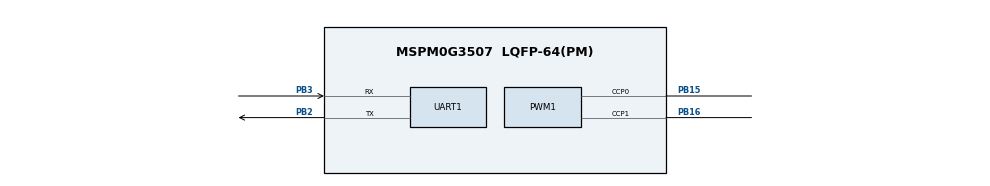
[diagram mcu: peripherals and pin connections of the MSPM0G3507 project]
//@cliArgs --device "MSPM0G350X" --package "LQFP-64(PM)" --part "Default"
//@v2CliArgs --device "MSPM0G3507" --package "LQFP-64(PM)"
// @cliArgs --board /ti/boards/LP_MSPM0G3507 --rtos nortos

/**
 * Import the modules used in this configuration.
 */
const SYSCTL = scripting.addModule("/ti/driverlib/SYSCTL");
const UART   = scripting.addModule("/ti/driverlib/UART", {}, false);
const UART1  = UART.addInstance();
const PWM    = scripting.addModule("/ti/driverlib/PWM", {}, false);
const PWM1   = PWM.addInstance();
const GPIO   = scripting.addModule("/ti/driverlib/GPIO", {}, false);
const GPIO1  = GPIO.addInstance();
const GPIO2  = GPIO.addInstance();
const GPIO3  = GPIO.addInstance();
const GPIO4  = GPIO.addInstance();
const GPIO5  = GPIO.addInstance();
const GPIO6  = GPIO.addInstance();
const GPIO7  = GPIO.addInstance();
const GPIO8  = GPIO.addInstance();
const GPIO9  = GPIO.addInstance();
const GPIO10 = GPIO.addInstance();
const GPIO11 = GPIO.addInstance();
const GPIO12 = GPIO.addInstance();
const GPIO13 = GPIO.addInstance();

/**
 * Write custom configuration values to the imported modules.
 */

const Board = scripting.addModule("/ti/driverlib/Board", {}, false);

SYSCTL.forceDefaultClkConfig = true;

UART1.$name = "UART_VISION";
UART1.profile = "CONFIG_PROFILE_1";
UART1.peripheral.$assign = "UART3";
UART1.targetBaudRate = 115200;
UART1.enableInternalLoopback = false;
UART1.enabledInterrupts = ["RX"];
UART1.enableFIFO = false;
UART1.peripheral.txPin.$assign = "PB2";
UART1.peripheral.rxPin.$assign = "PB3";

PWM1.$name                      = "PWM_MOTOR";
PWM1.pwmMode                    = "EDGE_ALIGN_UP";
PWM1.clockSource                = "BUSCLK";
PWM1.clockDivider               = 1;
PWM1.clockPrescale              = 1;
/* DriverLib writes LOAD = timerCount - 1: 32 MHz / 1600 = 20 kHz. */
PWM1.timerCount                 = 1600;
PWM1.timerStartTimer            = false;
PWM1.enableShadowLoad           = false;
PWM1.peripheral.$assign         = "TIMG8";
PWM1.peripheral.ccp0Pin.$assign = "PB15";
PWM1.peripheral.ccp1Pin.$assign = "PB16";
PWM1.PWM_CHANNEL_0.$name        = "MOTOR_A_PWM";
PWM1.PWM_CHANNEL_0.dutyCycle    = 0;
PWM1.PWM_CHANNEL_0.shadowUpdateMode = "IMMEDIATE";
PWM1.PWM_CHANNEL_1.$name        = "MOTOR_B_PWM";
PWM1.PWM_CHANNEL_1.dutyCycle    = 0;
PWM1.PWM_CHANNEL_1.shadowUpdateMode = "IMMEDIATE";

GPIO1.$name                             = "GPIO_TB6612_A";
GPIO1.port                              = "PORTA";
GPIO1.associatedPins.create(2);
GPIO1.associatedPins[0].$name           = "AIN2";
GPIO1.associatedPins[0].assignedPin     = "12";
GPIO1.associatedPins[0].initialValue    = "CLEARED";
GPIO1.associatedPins[1].$name           = "AIN1";
GPIO1.associatedPins[1].assignedPin     = "13";
GPIO1.associatedPins[1].initialValue    = "CLEARED";

GPIO2.$name                             = "GPIO_TB6612_B";
GPIO2.port                              = "PORTB";
GPIO2.associatedPins.create(2);
GPIO2.associatedPins[0].$name           = "BIN1";
GPIO2.associatedPins[0].assignedPin     = "0";
GPIO2.associatedPins[0].initialValue    = "CLEARED";
GPIO2.associatedPins[1].$name           = "BIN2";
GPIO2.associatedPins[1].assignedPin     = "1";
GPIO2.associatedPins[1].initialValue    = "CLEARED";

GPIO3.$name                              = "GPIO_ENCODERS";
GPIO3.port                               = "PORTA";
GPIO3.associatedPins.create(4);
GPIO3.associatedPins[0].$name            = "MOTOR_A_ENCA";
GPIO3.associatedPins[0].assignedPin      = "15";
GPIO3.associatedPins[0].direction        = "INPUT";
GPIO3.associatedPins[0].internalResistor = "PULL_UP";
GPIO3.associatedPins[0].interruptEn      = true;
GPIO3.associatedPins[0].polarity         = "RISE_FALL";
GPIO3.associatedPins[1].$name            = "MOTOR_A_ENCB";
GPIO3.associatedPins[1].assignedPin      = "16";
GPIO3.associatedPins[1].direction        = "INPUT";
GPIO3.associatedPins[1].internalResistor = "PULL_UP";
GPIO3.associatedPins[2].$name            = "MOTOR_B_ENCA";
GPIO3.associatedPins[2].assignedPin      = "17";
GPIO3.associatedPins[2].direction        = "INPUT";
GPIO3.associatedPins[2].internalResistor = "PULL_UP";
GPIO3.associatedPins[2].interruptEn      = true;
GPIO3.associatedPins[2].polarity         = "RISE_FALL";
GPIO3.associatedPins[3].$name            = "MOTOR_B_ENCB";
GPIO3.associatedPins[3].assignedPin      = "24";
GPIO3.associatedPins[3].direction        = "INPUT";
GPIO3.associatedPins[3].internalResistor = "PULL_UP";

GPIO4.$name                         = "GPIO_TRACK_A";
GPIO4.port                          = "PORTA";
GPIO4.associatedPins.create(2);
GPIO4.associatedPins[0].$name       = "S4";
GPIO4.associatedPins[0].assignedPin = "14";
GPIO4.associatedPins[0].direction   = "INPUT";
GPIO4.associatedPins[1].$name       = "S8";
GPIO4.associatedPins[1].assignedPin = "7";
GPIO4.associatedPins[1].direction   = "INPUT";

GPIO5.$name                         = "GPIO_TRACK_B";
GPIO5.port                          = "PORTB";
GPIO5.associatedPins.create(6);
GPIO5.associatedPins[0].$name       = "S1";
GPIO5.associatedPins[0].assignedPin = "25";
GPIO5.associatedPins[0].direction   = "INPUT";
GPIO5.associatedPins[1].$name       = "S2";
GPIO5.associatedPins[1].assignedPin = "24";
GPIO5.associatedPins[1].direction   = "INPUT";
GPIO5.associatedPins[2].$name       = "S3";
GPIO5.associatedPins[2].assignedPin = "20";
GPIO5.associatedPins[2].direction   = "INPUT";
GPIO5.associatedPins[3].$name       = "S5";
GPIO5.associatedPins[3].assignedPin = "18";
GPIO5.associatedPins[3].direction   = "INPUT";
GPIO5.associatedPins[4].$name       = "S6";
GPIO5.associatedPins[4].assignedPin = "19";
GPIO5.associatedPins[4].direction   = "INPUT";
GPIO5.associatedPins[5].$name       = "S7";
GPIO5.associatedPins[5].assignedPin = "10";
GPIO5.associatedPins[5].direction   = "INPUT";

GPIO6.$name                              = "GPIO_OLED";
GPIO6.port                               = "PORTA";
GPIO6.associatedPins.create(2);
GPIO6.associatedPins[0].$name            = "SDA";
GPIO6.associatedPins[0].assignedPin      = "28";
GPIO6.associatedPins[0].initialValue     = "SET";
GPIO6.associatedPins[1].$name            = "SCL";
GPIO6.associatedPins[1].assignedPin      = "31";
GPIO6.associatedPins[1].initialValue     = "SET";

GPIO7.$name                              = "GPIO_KEYS";
GPIO7.port                               = "PORTA";
GPIO7.associatedPins.create(3);
GPIO7.associatedPins[0].$name            = "K1";
GPIO7.associatedPins[0].assignedPin      = "26";
GPIO7.associatedPins[0].direction        = "INPUT";
GPIO7.associatedPins[0].internalResistor = "PULL_UP";
GPIO7.associatedPins[1].$name            = "K2";
GPIO7.associatedPins[1].assignedPin      = "25";
GPIO7.associatedPins[1].direction        = "INPUT";
GPIO7.associatedPins[1].internalResistor = "PULL_UP";
GPIO7.associatedPins[2].$name            = "K3";
GPIO7.associatedPins[2].assignedPin      = "27";
GPIO7.associatedPins[2].direction        = "INPUT";
GPIO7.associatedPins[2].internalResistor = "PULL_UP";

GPIO8.$name                              = "GPIO_IMU";
GPIO8.port                               = "PORTA";
GPIO8.associatedPins.create(2);
GPIO8.associatedPins[0].$name            = "IMU_SDA";
GPIO8.associatedPins[0].assignedPin      = "10";
GPIO8.associatedPins[0].initialValue     = "SET";
GPIO8.associatedPins[1].$name            = "IMU_SCL";
GPIO8.associatedPins[1].assignedPin      = "11";
GPIO8.associatedPins[1].initialValue     = "SET";

GPIO9.$name                              = "GPIO_ULTRASONIC";
GPIO9.port                               = "PORTA";
GPIO9.associatedPins.create(2);
GPIO9.associatedPins[0].$name            = "HC_TRIG";
GPIO9.associatedPins[0].assignedPin      = "8";
GPIO9.associatedPins[0].initialValue     = "CLEARED";
GPIO9.associatedPins[1].$name            = "HC_ECHO";
GPIO9.associatedPins[1].assignedPin      = "9";
GPIO9.associatedPins[1].direction        = "INPUT";

GPIO10.$name                             = "GPIO_SERVO";
GPIO10.port                              = "PORTB";
GPIO10.associatedPins.create(1);
GPIO10.associatedPins[0].$name           = "SERVO";
GPIO10.associatedPins[0].assignedPin     = "9";
GPIO10.associatedPins[0].initialValue    = "CLEARED";

GPIO11.$name                             = "GPIO_GIMBAL_A";
GPIO11.port                              = "PORTA";
GPIO11.associatedPins.create(2);
GPIO11.associatedPins[0].$name           = "PITCH_DIR";
GPIO11.associatedPins[0].assignedPin     = "1";
GPIO11.associatedPins[0].initialValue    = "CLEARED";
GPIO11.associatedPins[1].$name           = "PITCH_EN";
GPIO11.associatedPins[1].assignedPin     = "2";
GPIO11.associatedPins[1].initialValue    = "SET";

GPIO12.$name                             = "GPIO_GIMBAL_B";
GPIO12.port                              = "PORTB";
GPIO12.associatedPins.create(1);
GPIO12.associatedPins[0].$name           = "PITCH_STEP";
GPIO12.associatedPins[0].assignedPin     = "4";
GPIO12.associatedPins[0].initialValue    = "CLEARED";

GPIO13.$name                             = "GPIO_GIMBAL_PITCH";
GPIO13.port                              = "PORTB";
GPIO13.associatedPins.create(3);
GPIO13.associatedPins[0].$name           = "STEP";
GPIO13.associatedPins[0].assignedPin     = "5";
GPIO13.associatedPins[0].initialValue    = "CLEARED";
GPIO13.associatedPins[1].$name           = "DIR";
GPIO13.associatedPins[1].assignedPin     = "6";
GPIO13.associatedPins[1].initialValue    = "CLEARED";
GPIO13.associatedPins[2].$name           = "EN";
GPIO13.associatedPins[2].assignedPin     = "7";
GPIO13.associatedPins[2].initialValue    = "CLEARED";
